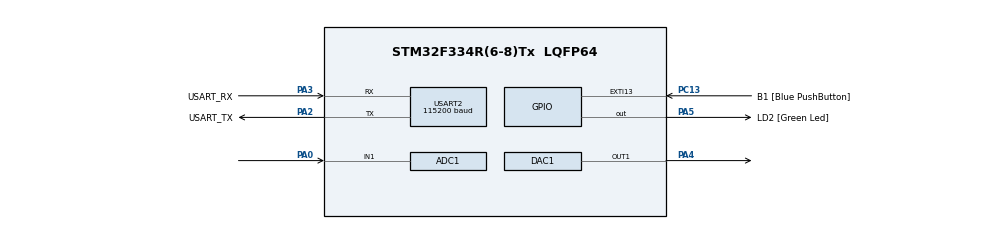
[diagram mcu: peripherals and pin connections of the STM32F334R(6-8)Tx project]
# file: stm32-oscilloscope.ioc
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ADC1.Channel-0\#ChannelRegularConversion=ADC_CHANNEL_1
ADC1.ClockPrescaler=ADC_CLOCK_SYNC_PCLK_DIV1
ADC1.DMAContinuousRequests=ENABLE
ADC1.ExternalTrigConv=ADC_EXTERNALTRIGCONV_T3_TRGO
ADC1.NbrOfConversion=1
ADC1.NbrOfConversionFlag=1
ADC1.Offset-0\#ChannelRegularConversion=0
ADC1.OffsetNumber-0\#ChannelRegularConversion=ADC_OFFSET_NONE
ADC1.Rank-0\#ChannelRegularConversion=1
ADC1.SamplingTime-0\#ChannelRegularConversion=ADC_SAMPLETIME_181CYCLES_5
ADC1.SamplingTimeOPAMP-0\#ChannelRegularConversion=ADC_SAMPLETIME_61CYCLES_5
ADC1.SubFamily=STM32F334x8
ADC1.master=1
DAC1.DAC_OutputBuffer=DAC_OUTPUTBUFFER_DISABLE
DAC1.DAC_Trigger=DAC_TRIGGER_T6_TRGO
Dma.ADC1.0.Direction=DMA_PERIPH_TO_MEMORY
Dma.ADC1.0.Instance=DMA1_Channel1
Dma.ADC1.0.MemDataAlignment=DMA_MDATAALIGN_HALFWORD
Dma.ADC1.0.MemInc=DMA_MINC_ENABLE
Dma.ADC1.0.Mode=DMA_CIRCULAR
Dma.ADC1.0.PeriphDataAlignment=DMA_PDATAALIGN_HALFWORD
Dma.ADC1.0.PeriphInc=DMA_PINC_DISABLE
Dma.ADC1.0.Priority=DMA_PRIORITY_VERY_HIGH
Dma.DAC1_CH1.2.Direction=DMA_MEMORY_TO_PERIPH
Dma.DAC1_CH1.2.Instance=DMA1_Channel3
Dma.DAC1_CH1.2.MemDataAlignment=DMA_MDATAALIGN_HALFWORD
Dma.DAC1_CH1.2.MemInc=DMA_MINC_ENABLE
Dma.DAC1_CH1.2.Mode=DMA_CIRCULAR
Dma.DAC1_CH1.2.PeriphDataAlignment=DMA_PDATAALIGN_HALFWORD
Dma.DAC1_CH1.2.PeriphInc=DMA_PINC_DISABLE
Dma.DAC1_CH1.2.Priority=DMA_PRIORITY_HIGH
Dma.Request0=ADC1
Dma.Request1=USART2_TX
Dma.Request2=DAC1_CH1
Dma.USART2_TX.1.Direction=DMA_MEMORY_TO_PERIPH
Dma.USART2_TX.1.Instance=DMA1_Channel7
Dma.USART2_TX.1.MemDataAlignment=DMA_MDATAALIGN_BYTE
Dma.USART2_TX.1.MemInc=DMA_MINC_ENABLE
Dma.USART2_TX.1.Mode=DMA_NORMAL
Dma.USART2_TX.1.PeriphDataAlignment=DMA_PDATAALIGN_BYTE
Dma.USART2_TX.1.PeriphInc=DMA_PINC_DISABLE
Dma.USART2_TX.1.Priority=DMA_PRIORITY_LOW
Mcu.Family=STM32F3
Mcu.Name=STM32F334R(6-8)Tx
Mcu.Package=LQFP64
NVIC.DMA1_Channel1_IRQn=true\:0\:0\:false\:false\:false\:false\:true\:true
NVIC.DMA1_Channel7_IRQn=true\:1\:0\:true\:false\:true\:true\:true\:true
NVIC.PriorityGroup=NVIC_PRIORITYGROUP_2
NVIC.TIM2_IRQn=true\:3\:0\:true\:false\:false\:true\:true\:true
NVIC.USART2_IRQn=true\:2\:0\:true\:false\:true\:true\:true\:true
PA0.Mode=IN1-Single-Ended
PA0.Signal=ADC1_IN1
PA13.GPIO_Label=TMS
PA13.Mode=Serial_Wire
PA13.Signal=SYS_JTMS-SWDIO
PA14.GPIO_Label=TCK
PA14.Mode=Serial_Wire
PA14.Signal=SYS_JTCK-SWCLK
PA2.GPIO_Label=USART_TX
PA2.Mode=Asynchronous
PA2.Signal=USART2_TX
PA3.GPIO_Label=USART_RX
PA3.Mode=Asynchronous
PA3.Signal=USART2_RX
PA4.Signal=COMP_DAC11_group
PA5.GPIO_Label=LD2 [Green Led]
PA5.Signal=GPIO_Output
PB3.GPIO_Label=SWO
PB3.Signal=SYS_JTDO-TRACESWO
PC13.GPIO_Label=B1 [Blue PushButton]
PC13.GPIO_ModeDefaultEXTI=GPIO_MODE_IT_FALLING
PC13.Signal=GPXTI13
PC14\ /\ OSC32_IN.Signal=RCC_OSC32_IN
PC15\ /\ OSC32_OUT.GPIO_Label=RCC_OSC32_OUT
PC15\ /\ OSC32_OUT.Signal=RCC_OSC32_OUT
PF0\ /\ OSC_IN.Mode=HSE-External-Clock-Source
PF0\ /\ OSC_IN.Signal=RCC_OSC_IN
PF1\ /\ OSC_OUT.Signal=RCC_OSC_OUT
ProjectManager.HeapSize=0x200
ProjectManager.StackSize=0x800
ProjectManager.TargetToolchain=CMake
RCC.AHBFreq_Value=72000000
RCC.APB1CLKDivider=RCC_HCLK_DIV2
RCC.APB1Freq_Value=36000000
RCC.APB1TimFreq_Value=72000000
RCC.APB2Freq_Value=72000000
RCC.APB2TimFreq_Value=72000000
RCC.CortexFreq_Value=72000000
RCC.FLatency-AdvancedSettings=FLASH_LATENCY_2
RCC.HCLKFreq_Value=72000000
RCC.HSE_VALUE=8000000
RCC.HSI_VALUE=8000000
RCC.LSE_VALUE=32768
RCC.PLLMUL=RCC_PLL_MUL9
RCC.PLLSourceVirtual=RCC_PLLSOURCE_HSE
RCC.SYSCLKFreq_VALUE=72000000
RCC.SYSCLKSourceVirtual=RCC_SYSCLKSOURCE_PLLCLK
SH.COMP_DAC11_group.0=DAC1_OUT1,DAC_OUT1
TIM2.AutoReloadPreload=TIM_AUTORELOAD_PRELOAD_ENABLE
TIM2.Period=999
TIM2.Prescaler=35999
TIM3.Period=999
TIM3.Prescaler=71
TIM3.TIM_MasterOutputTrigger=TIM_TRGO_UPDATE
TIM6.TIM_MasterOutputTrigger=TIM_TRGO_UPDATE
USART2.BaudRate=115200
USART2.VirtualMode-Asynchronous=VM_ASYNC
VP_TIM2_VS_ClockSourceINT.Mode=Internal
VP_TIM3_VS_ClockSourceINT.Mode=Internal
VP_TIM6_VS_ClockSourceINT.Mode=Enable_Timer
board=NUCLEO-F334R8

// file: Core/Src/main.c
/* USER CODE BEGIN Header */
/**
  ******************************************************************************
  * @file           : main.c
  * @brief          : Main program body
  ******************************************************************************
  * @attention
  *
  * Copyright (c) 2026 STMicroelectronics.
  * All rights reserved.
  *
  * This software is licensed under terms that can be found in the LICENSE file
  * in the root directory of this software component.
  * If no LICENSE file comes with this software, it is provided AS-IS.
  *
  ******************************************************************************
  */
/* USER CODE END Header */
#include "main.h"
#include "adc.h"
#include "dac.h"
#include "dma.h"
#include "tim.h"
#include "usart.h"
#include "gpio.h"

/* USER CODE BEGIN Includes */
#include "app.h"

/* USER CODE END Includes */

void SystemClock_Config(void);

int main(void)
{

  /* MCU Configuration--------------------------------------------------------*/

  /* Reset of all peripherals, Initializes the Flash interface and the Systick. */
  LL_APB2_GRP1_EnableClock(LL_APB2_GRP1_PERIPH_SYSCFG);
  LL_APB1_GRP1_EnableClock(LL_APB1_GRP1_PERIPH_PWR);

  /* System interrupt init*/
  NVIC_SetPriorityGrouping(NVIC_PRIORITYGROUP_2);

  /* Configure the system clock */
  SystemClock_Config();

  /* Initialize all configured peripherals */
  MX_GPIO_Init();
  MX_DMA_Init();
  MX_USART2_UART_Init();
  MX_ADC1_Init();
  MX_TIM3_Init();
  MX_DAC1_Init();
  MX_TIM6_Init();
  MX_TIM2_Init();
  /* USER CODE BEGIN 2 */
  app_main(); /* C++ application, does not return */

  /* USER CODE END 2 */

  /* Infinite loop */
  while (1)
  {

  }
}

void SystemClock_Config(void)
{
  LL_FLASH_SetLatency(LL_FLASH_LATENCY_2);
  while(LL_FLASH_GetLatency()!= LL_FLASH_LATENCY_2)
  {
  }
  LL_RCC_HSE_EnableBypass();
  LL_RCC_HSE_Enable();

   /* Wait till HSE is ready */
  while(LL_RCC_HSE_IsReady() != 1)
  {

  }
  LL_RCC_PLL_ConfigDomain_SYS(LL_RCC_PLLSOURCE_HSE_DIV_1, LL_RCC_PLL_MUL_9);
  LL_RCC_PLL_Enable();

   /* Wait till PLL is ready */
  while(LL_RCC_PLL_IsReady() != 1)
  {

  }
  LL_RCC_SetAHBPrescaler(LL_RCC_SYSCLK_DIV_1);
  LL_RCC_SetAPB1Prescaler(LL_RCC_APB1_DIV_2);
  LL_RCC_SetAPB2Prescaler(LL_RCC_APB2_DIV_1);
  LL_RCC_SetSysClkSource(LL_RCC_SYS_CLKSOURCE_PLL);

   /* Wait till System clock is ready */
  while(LL_RCC_GetSysClkSource() != LL_RCC_SYS_CLKSOURCE_STATUS_PLL)
  {

  }
  LL_Init1msTick(72000000);
  LL_SetSystemCoreClock(72000000);
}

void Error_Handler(void)
{
  __disable_irq();
  while (1)
  {
  }
}
